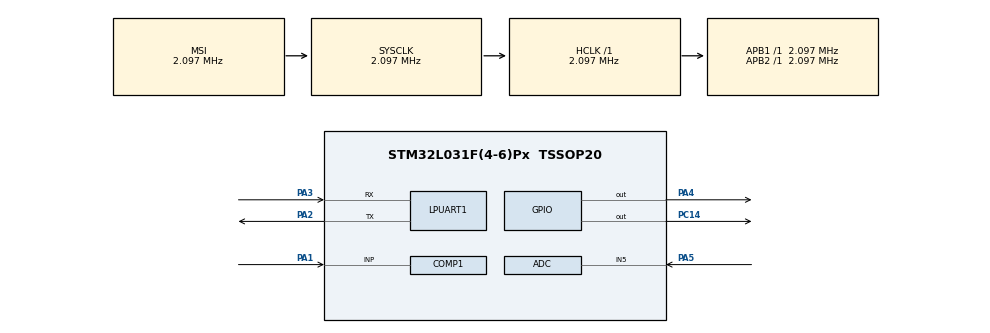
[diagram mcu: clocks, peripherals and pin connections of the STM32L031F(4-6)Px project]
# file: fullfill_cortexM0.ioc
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COMP1.InvertingInput=COMP_INPUT_MINUS_VREFINT
COMP1.Mode=COMP_POWERMODE_ULTRALOWPOWER
COMP1.NonInvertingInput=COMP_INPUT_PLUS_IO1
LPUART1.HwFlowCtl-Asynchronous=UART_HWCONTROL_NONE
Mcu.Family=STM32L0
Mcu.Name=STM32L031F(4-6)Px
Mcu.Package=TSSOP20
PA1.Mode=INP
PA1.Signal=COMP1_INP
PA13.Mode=Serial_Wire
PA13.Signal=SYS_SWDIO
PA14.Mode=Serial_Wire
PA14.Signal=SYS_SWCLK
PA2.Mode=Asynchronous
PA2.Signal=LPUART1_TX
PA3.Mode=Asynchronous
PA3.Signal=LPUART1_RX
PA4.Signal=GPIO_Output
PA5.Mode=IN5
PA5.Signal=ADC_IN5
PC14-OSC32_IN.Signal=GPIO_Output
ProjectManager.HeapSize=0x200
ProjectManager.StackSize=0x400
ProjectManager.TargetToolchain=SW4STM32
RCC.48MEnable=false
RCC.ADCEnable=false
RCC.AHBFreq_Value=2097000
RCC.APB1Freq_Value=2097000
RCC.APB1TimFreq_Value=2097000
RCC.APB2Freq_Value=2097000
RCC.APB2TimFreq_Value=2097000
RCC.ClockTypeHCLK=RCC_CLOCKTYPE_HCLK
RCC.ClockTypePCLK1=RCC_CLOCKTYPE_PCLK1
RCC.ClockTypePCLK2=RCC_CLOCKTYPE_PCLK2
RCC.ClockTypeSysClk=RCC_CLOCKTYPE_SYSCLK
RCC.EnableCSSLSE=false
RCC.EnableHSE=false
RCC.EnableHSELCDDevisor=false
RCC.EnableHSERTCDevisor=false
RCC.EnableLSE=false
RCC.EnableLSERTC=false
RCC.EnbaleCSS=false
RCC.HSE_VALUE=8000000
RCC.HSI16State=RCC_HSI_OFF
RCC.HSI16_VALUE=16000000
RCC.HSI48State=RCC_HSI48_OFF
RCC.HSI_VALUE=16000000
RCC.I2C1Enable=false
RCC.IWDGEnable=false
RCC.LCDEnable=false
RCC.LPTIMEnable=false
RCC.LPUARTEnable=true
RCC.LSE_VALUE=32768
RCC.LSIState=RCC_LSI_OFF
RCC.MCOEnable=false
RCC.MSI_VALUE=2097000
RCC.PLLSource=RCC_PLLSOURCE_HSI
RCC.PLLState=RCC_PLL_OFF
RCC.RCC_PERIPHCLK_LPUART1Var=RCC_PERIPHCLK_LPUART1
RCC.RNGEnable=false
RCC.RTCEnable=false
RCC.SYSCLKFreq_VALUE=2097000
RCC.USART1Enable=false
RCC.USART2Enable=false
RCC.USBEnable=false
RCC.VCOOutputFreq_Value=48000000
VP_COMP1_VS_VREFINT.Mode=VREFINT
board=fullfill_cortexM0

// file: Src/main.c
/**
  ******************************************************************************
  * File Name          : main.c
  * Description        : Main program body
  ******************************************************************************
  *
  * COPYRIGHT(c) 2017 STMicroelectronics
  *
  * Redistribution and use in source and binary forms, with or without modification,
  * are permitted provided that the following conditions are met:
  *   1. Redistributions of source code must retain the above copyright notice,
  *      this list of conditions and the following disclaimer.
  *   2. Redistributions in binary form must reproduce the above copyright notice,
  *      this list of conditions and the following disclaimer in the documentation
  *      and/or other materials provided with the distribution.
  *   3. Neither the name of STMicroelectronics nor the names of its contributors
  *      may be used to endorse or promote products derived from this software
  *      without specific prior written permission.
  *
  * THIS SOFTWARE IS PROVIDED BY THE COPYRIGHT HOLDERS AND CONTRIBUTORS "AS IS"
  * AND ANY EXPRESS OR IMPLIED WARRANTIES, INCLUDING, BUT NOT LIMITED TO, THE
  * IMPLIED WARRANTIES OF MERCHANTABILITY AND FITNESS FOR A PARTICULAR PURPOSE ARE
  * DISCLAIMED. IN NO EVENT SHALL THE COPYRIGHT HOLDER OR CONTRIBUTORS BE LIABLE
  * FOR ANY DIRECT, INDIRECT, INCIDENTAL, SPECIAL, EXEMPLARY, OR CONSEQUENTIAL
  * DAMAGES (INCLUDING, BUT NOT LIMITED TO, PROCUREMENT OF SUBSTITUTE GOODS OR
  * SERVICES; LOSS OF USE, DATA, OR PROFITS; OR BUSINESS INTERRUPTION) HOWEVER
  * CAUSED AND ON ANY THEORY OF LIABILITY, WHETHER IN CONTRACT, STRICT LIABILITY,
  * OR TORT (INCLUDING NEGLIGENCE OR OTHERWISE) ARISING IN ANY WAY OUT OF THE USE
  * OF THIS SOFTWARE, EVEN IF ADVISED OF THE POSSIBILITY OF SUCH DAMAGE.
  *
  ******************************************************************************
  */
#include "main.h"
#include "stm32l0xx_hal.h"
#include "adc.h"
#include "comp.h"
#include "usart.h"
#include "gpio.h"

#define GPIO_TX	GPIOA, GPIO_PIN_2
//#define GPIO_XBEE_SLEEP GPIO GPIOA, GPIO_PIN_4
//#define GPIO_ACTIVATE_SENSOR GPIOC, GPIO_PIN_14

/* USER CODE BEGIN PV */
/* Private variables ---------------------------------------------------------*/

/* USER CODE END PV */

void SystemClock_Config(void);
void Error_Handler(void);

/* USER CODE BEGIN PFP */
/* Private function prototypes -----------------------------------------------*/

/* USER CODE END PFP */

int main(void)
{

  /* MCU Configuration----------------------------------------------------------*/

  /* Reset of all peripherals, Initializes the Flash interface and the Systick. */
  HAL_Init();

  /* Configure the system clock */
  SystemClock_Config();

  /* Initialize all configured peripherals */
  MX_GPIO_Init();
  MX_COMP1_Init();
  MX_ADC_Init();
  MX_LPUART1_UART_Init();

  /* Infinite loop */
  /* USER CODE BEGIN WHILE */

  uint8_t* pData= 'a';

  while (1)
  {
	  //HAL_GPIO_WritePin(GPIO_ACTIVATE_SENSOR,0);
	  //HAL_GPIO_WritePin(GPIO_XBEE_SLEEP,1);
	  //HAL_Delay(100);
	  //HAL_GPIO_WritePin(GPIO_ACTIVATE_SENSOR,1);
	  //HAL_GPIO_WritePin(GPIO_XBEE_SLEEP,0);
	  //HAL_Delay(100);
	   HAL_UART_Transmit(&hlpuart1, pData, 1, 1);
	   HAL_Delay(1000);
  /* USER CODE END WHILE */

  }

}

/** System Clock Configuration
*/
void SystemClock_Config(void)
{

  RCC_OscInitTypeDef RCC_OscInitStruct;
  RCC_ClkInitTypeDef RCC_ClkInitStruct;
  RCC_PeriphCLKInitTypeDef PeriphClkInit;

    /**Configure the main internal regulator output voltage
    */
  __HAL_PWR_VOLTAGESCALING_CONFIG(PWR_REGULATOR_VOLTAGE_SCALE1);

    /**Initializes the CPU, AHB and APB busses clocks
    */
  RCC_OscInitStruct.OscillatorType = RCC_OSCILLATORTYPE_MSI;
  RCC_OscInitStruct.MSIState = RCC_MSI_ON;
  RCC_OscInitStruct.MSICalibrationValue = 0;
  RCC_OscInitStruct.MSIClockRange = RCC_MSIRANGE_5;
  RCC_OscInitStruct.PLL.PLLState = RCC_PLL_NONE;
  if (HAL_RCC_OscConfig(&RCC_OscInitStruct) != HAL_OK)
  {
    Error_Handler();
  }

    /**Initializes the CPU, AHB and APB busses clocks
    */
  RCC_ClkInitStruct.ClockType = RCC_CLOCKTYPE_HCLK|RCC_CLOCKTYPE_SYSCLK
                              |RCC_CLOCKTYPE_PCLK1|RCC_CLOCKTYPE_PCLK2;
  RCC_ClkInitStruct.SYSCLKSource = RCC_SYSCLKSOURCE_MSI;
  RCC_ClkInitStruct.AHBCLKDivider = RCC_SYSCLK_DIV1;
  RCC_ClkInitStruct.APB1CLKDivider = RCC_HCLK_DIV1;
  RCC_ClkInitStruct.APB2CLKDivider = RCC_HCLK_DIV1;

  if (HAL_RCC_ClockConfig(&RCC_ClkInitStruct, FLASH_LATENCY_0) != HAL_OK)
  {
    Error_Handler();
  }

  PeriphClkInit.PeriphClockSelection = RCC_PERIPHCLK_LPUART1;
  PeriphClkInit.Lpuart1ClockSelection = RCC_LPUART1CLKSOURCE_PCLK1;
  if (HAL_RCCEx_PeriphCLKConfig(&PeriphClkInit) != HAL_OK)
  {
    Error_Handler();
  }

    /**Configure the Systick interrupt time
    */
  HAL_SYSTICK_Config(HAL_RCC_GetHCLKFreq()/1000);

    /**Configure the Systick
    */
  HAL_SYSTICK_CLKSourceConfig(SYSTICK_CLKSOURCE_HCLK);

  /* SysTick_IRQn interrupt configuration */
  HAL_NVIC_SetPriority(SysTick_IRQn, 0, 0);
}

void Error_Handler(void)
{
  while(1)
  {
  }
}

/************************ (C) COPYRIGHT STMicroelectronics *****END OF FILE****/
